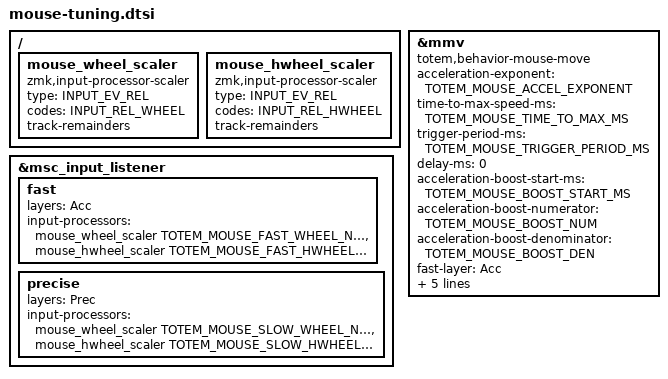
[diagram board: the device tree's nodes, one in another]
#include "mouse-tuning.h"

&mmv {
    compatible = "totem,behavior-mouse-move";
    acceleration-exponent = <TOTEM_MOUSE_ACCEL_EXPONENT>;
    time-to-max-speed-ms = <TOTEM_MOUSE_TIME_TO_MAX_MS>;
    trigger-period-ms = <TOTEM_MOUSE_TRIGGER_PERIOD_MS>;
    delay-ms = <0>;
    acceleration-boost-start-ms = <TOTEM_MOUSE_BOOST_START_MS>;
    acceleration-boost-numerator = <TOTEM_MOUSE_BOOST_NUM>;
    acceleration-boost-denominator = <TOTEM_MOUSE_BOOST_DEN>;
    fast-layer = <Acc>;
    precise-layer = <Prec>;
    fast-speed = <TOTEM_MOUSE_FAST_SPEED_NUM TOTEM_MOUSE_FAST_SPEED_DEN>;
    precise-speed = <TOTEM_MOUSE_SLOW_SPEED_NUM TOTEM_MOUSE_SLOW_SPEED_DEN>;
};

/ {
    mouse_wheel_scaler: mouse_wheel_scaler {
        compatible = "zmk,input-processor-scaler";
        #input-processor-cells = <2>;
        type = <INPUT_EV_REL>;
        codes = <INPUT_REL_WHEEL>;
        track-remainders;
    };
    mouse_hwheel_scaler: mouse_hwheel_scaler {
        compatible = "zmk,input-processor-scaler";
        #input-processor-cells = <2>;
        type = <INPUT_EV_REL>;
        codes = <INPUT_REL_HWHEEL>;
        track-remainders;
    };
};

&msc_input_listener {
    fast {
        layers = <Acc>;
        input-processors =
            <&mouse_wheel_scaler TOTEM_MOUSE_FAST_WHEEL_NUM TOTEM_MOUSE_FAST_WHEEL_DEN>,
            <&mouse_hwheel_scaler TOTEM_MOUSE_FAST_HWHEEL_NUM TOTEM_MOUSE_FAST_HWHEEL_DEN>;
    };
    precise {
        layers = <Prec>;
        input-processors =
            <&mouse_wheel_scaler TOTEM_MOUSE_SLOW_WHEEL_NUM TOTEM_MOUSE_SLOW_WHEEL_DEN>,
            <&mouse_hwheel_scaler TOTEM_MOUSE_SLOW_HWHEEL_NUM TOTEM_MOUSE_SLOW_HWHEEL_DEN>;
    };
};
